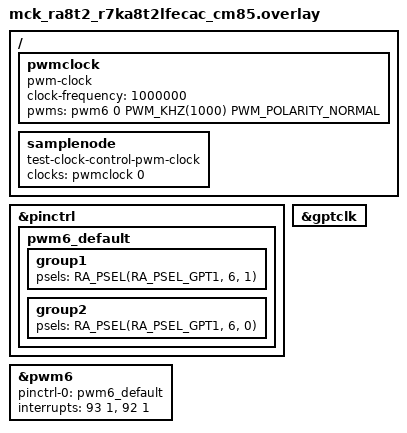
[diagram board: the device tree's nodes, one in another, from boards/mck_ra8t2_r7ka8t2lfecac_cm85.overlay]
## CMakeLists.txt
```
# SPDX-License-Identifier: Apache-2.0

cmake_minimum_required(VERSION 3.28.0)
find_package(Zephyr REQUIRED HINTS $ENV{ZEPHYR_BASE})
project(pwm_clock)

target_sources(app PRIVATE src/main.c)
```

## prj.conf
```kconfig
CONFIG_ZTEST=y
CONFIG_CLOCK_CONTROL=y
```

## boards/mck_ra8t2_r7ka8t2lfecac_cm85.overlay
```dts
/*
 * Copyright (c) 2025 Renesas Electronics Corporation
 *
 * SPDX-License-Identifier: Apache-2.0
 */

#include <zephyr/dt-bindings/pwm/pwm.h>

/ {
	pwmclock: pwmclock {
		status = "okay";
		compatible = "pwm-clock";
		#clock-cells = <1>;
		clock-frequency = <1000000>;
		pwms = <&pwm6 0 PWM_KHZ(1000) PWM_POLARITY_NORMAL>;
	};

	samplenode: samplenode {
		status = "okay";
		compatible = "test-clock-control-pwm-clock";
		clocks = <&pwmclock 0>;
	};
};

&pinctrl {
	pwm6_default: pwm6_default {
		group1 {
			/* GTIOC6A */
			psels = <RA_PSEL(RA_PSEL_GPT1, 6, 1)>;
		};

		group2 {
			/* GTIOC6B */
			psels = <RA_PSEL(RA_PSEL_GPT1, 6, 0)>;
		};
	};
};

&gptclk {
	status = "okay";
};

&pwm6 {
	pinctrl-0 = <&pwm6_default>;
	pinctrl-names = "default";
	interrupts = <93 1>, <92 1>;
	interrupt-names = "gtioca", "overflow";
	status = "okay";
};
```

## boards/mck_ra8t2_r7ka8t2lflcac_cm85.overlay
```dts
/*
 * Copyright (c) 2025 Renesas Electronics Corporation
 *
 * SPDX-License-Identifier: Apache-2.0
 */

#include <zephyr/dt-bindings/pwm/pwm.h>

/ {
	pwmclock: pwmclock {
		compatible = "pwm-clock";
		#clock-cells = <1>;
		clock-frequency = <1000000>;
		pwms = <&pwm6 0 PWM_KHZ(1000) PWM_POLARITY_NORMAL>;
		status = "okay";
	};

	samplenode: samplenode {
		compatible = "test-clock-control-pwm-clock";
		clocks = <&pwmclock 0>;
		status = "okay";
	};
};

&pinctrl {
	pwm6_default: pwm6_default {
		group1 {
			/* GTIOC6A */
			psels = <RA_PSEL(RA_PSEL_GPT1, 6, 1)>;
		};

		group2 {
			/* GTIOC6B */
			psels = <RA_PSEL(RA_PSEL_GPT1, 6, 0)>;
		};
	};
};

&gptclk {
	status = "okay";
};

&pwm6 {
	pinctrl-0 = <&pwm6_default>;
	pinctrl-names = "default";
	interrupts = <93 1>, <92 1>;
	interrupt-names = "gtioca", "overflow";
	status = "okay";
};
```

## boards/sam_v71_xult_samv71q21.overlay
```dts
/*
 * Copyright (c) 2023 Andriy Gelman
 *
 * SPDX-License-Identifier: Apache-2.0
 */

/ {
	pwmclock: pwmclock {
		compatible = "pwm-clock";
		#clock-cells = <1>;
		clock-frequency = <1000000>;
		pwms = <&pwm0 0 PWM_KHZ(1000) PWM_POLARITY_NORMAL>;
		status = "okay";
	};

	samplenode: samplenode {
		compatible = "test-clock-control-pwm-clock";
		clocks = <&pwmclock 0>;
		status = "okay";
	};
};

&pwm0 {
	prescaler = <1>;
};
```

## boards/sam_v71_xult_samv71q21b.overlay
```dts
/*
 * Copyright (c) 2023 Andriy Gelman
 *
 * SPDX-License-Identifier: Apache-2.0
 */

#include "sam_v71_xult_samv71q21.overlay"
```

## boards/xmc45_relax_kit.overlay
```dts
/*
 * Copyright (c) 2023 Andriy Gelman
 *
 * SPDX-License-Identifier: Apache-2.0
 */

/ {
	pwmclock: pwmclock {
		compatible = "pwm-clock";
		#clock-cells = <1>;
		clock-frequency = <1000000>;
		pwms = <&pwm_ccu40 2 PWM_KHZ(1000) PWM_POLARITY_NORMAL>;
		status = "okay";
	};

	samplenode: samplenode {
		compatible = "test-clock-control-pwm-clock";
		clocks = <&pwmclock 0>;
		status = "okay";
	};
};

&pwm_ccu40 {
	slice-prescaler = <0 0 0 0>;
	status = "okay";
};
```

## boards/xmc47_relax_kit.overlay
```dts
/*
 * Copyright (c) 2023 Andriy Gelman
 *
 * SPDX-License-Identifier: Apache-2.0
 */

/ {
	pwmclock: pwmclock {
		compatible = "pwm-clock";
		#clock-cells = <1>;
		clock-frequency = <1000000>;
		pwms = <&pwm_ccu80 0 PWM_KHZ(1000) PWM_POLARITY_NORMAL>;
		status = "okay";
	};

	samplenode: samplenode {
		compatible = "test-clock-control-pwm-clock";
		clocks = <&pwmclock 0>;
		status = "okay";
	};
};

&pwm_ccu80 {
	slice-prescaler = <0 0 0 0>;
	status = "okay";
};
```

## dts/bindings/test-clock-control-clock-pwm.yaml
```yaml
description: Example binding for a node using a PWM clock

compatible: "test-clock-control-pwm-clock"

include: base.yaml

properties:
  clocks:
    required: true
    description: Clock phandle array
```

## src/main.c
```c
/*
 * Copyright (c) 2023 Andriy Gelman <andriy.gelman@gmail.com>
 *
 * SPDX-License-Identifier: Apache-2.0
 */

#include <zephyr/kernel.h>
#include <zephyr/sys/printk.h>
#include <zephyr/device.h>
#include <zephyr/devicetree.h>
#include <zephyr/drivers/clock_control.h>
#include <zephyr/ztest.h>

#define NODELABEL DT_NODELABEL(samplenode)
static const struct device *clk_dev = DEVICE_DT_GET(DT_CLOCKS_CTLR(NODELABEL));

static void *pwm_clock_setup(void)
{
	int ret;
	uint32_t clock_rate;
	uint32_t clock_rate_dt = DT_PROP_BY_PHANDLE(NODELABEL, clocks, clock_frequency);

	zassert_equal(device_is_ready(clk_dev), true, "%s: PWM clock device is not ready",
		      clk_dev->name);

	ret = clock_control_get_rate(clk_dev, 0, &clock_rate);
	zassert_equal(0, ret, "%s: Unexpected err (%d) from clock_control_get_rate",
		      clk_dev->name, ret);

	zassert_equal(clock_rate_dt, clock_rate,
		      "%s: devicetree clock rate mismatch. Expected %dHz Fetched %dHz",
		      clk_dev->name, clock_rate_dt, clock_rate);

	zassert_equal(clock_control_get_status(clk_dev, 0), CLOCK_CONTROL_STATUS_OFF,
		      "%s: PWM clock should initially be off", clk_dev->name);

	ret = clock_control_on(clk_dev, 0);
	zassert_equal(0, ret, "%s: Unexpected err (%d) from clock_control_on", clk_dev->name, ret);

	return NULL;
}

ZTEST(pwm_clock, test_clock_control_get_status)
{
	zassert_equal(clock_control_get_status(clk_dev, 0), CLOCK_CONTROL_STATUS_ON,
		      "%s: PWM clock should be on", clk_dev->name);
	zassert_equal(clock_control_get_status(clk_dev, (clock_control_subsys_t)1),
		      CLOCK_CONTROL_STATUS_UNKNOWN, "%s: Invalid clock ID should return unknown",
		      clk_dev->name);
}

ZTEST(pwm_clock, test_clock_control_get_rate)
{
	int ret;
	uint32_t clock_rate;

	ret = clock_control_get_rate(clk_dev, 0, &clock_rate);
	zassert_equal(0, ret, "%s: Unexpected err (%d) from clock_control_get_rate",
		      clk_dev->name, ret);
}

ZTEST(pwm_clock, test_clock_control_set_rate)
{
	int ret;
	uint32_t clock_rate, clock_rate_new;

	ret = clock_control_get_rate(clk_dev, 0, &clock_rate);
	zassert_equal(0, ret, "%s: Unexpected err (%d) from clock_control_get_rate",
		      clk_dev->name, ret);

	clock_rate /= 2;

	ret = clock_control_set_rate(clk_dev, 0, (clock_control_subsys_rate_t)clock_rate);
	zassert_equal(0, ret, "%s: unexpected err (%d) from clock_control_set_rate",
		      clk_dev->name, ret);

	ret = clock_control_get_rate(clk_dev, 0, &clock_rate_new);
	zassert_equal(0, ret, "%s: Unexpected err (%d) from clock_control_get_rate",
		      clk_dev->name, ret);

	zassert_equal(clock_rate, clock_rate_new,
		      "%s: Clock rate mismatch. Expected %dHz Fetched %dHz", clk_dev->name,
		      clock_rate, clock_rate_new);
}

ZTEST_SUITE(pwm_clock, NULL, pwm_clock_setup, NULL, NULL, NULL);
```
